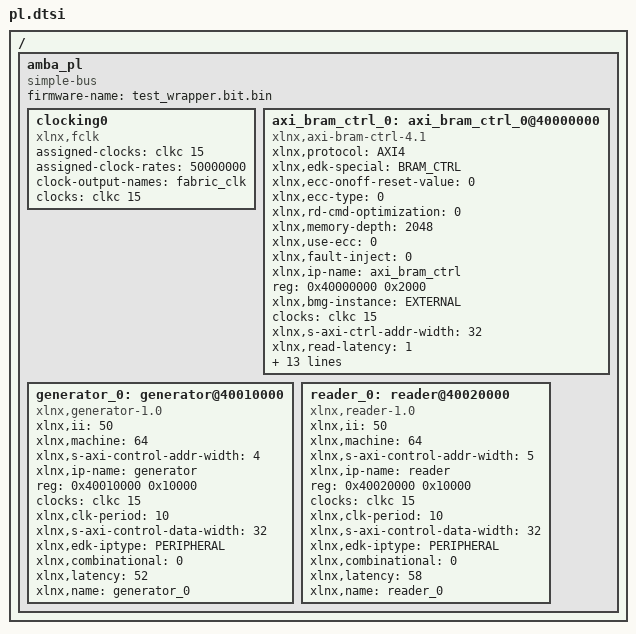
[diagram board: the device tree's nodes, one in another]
/ {
	amba_pl: amba_pl {
		ranges;
		compatible = "simple-bus";
		#address-cells = <1>;
		#size-cells = <1>;
		firmware-name = "test_wrapper.bit.bin";
		clocking0: clocking0 {
			compatible = "xlnx,fclk";
			assigned-clocks = <&clkc 15>;
			assigned-clock-rates = <50000000>;
			#clock-cells = <0>;
			clock-output-names = "fabric_clk";
			clocks = <&clkc 15>;
		};
		axi_bram_ctrl_0: axi_bram_ctrl_0@40000000 {
			xlnx,protocol = "AXI4";
			xlnx,edk-special = "BRAM_CTRL";
			compatible = "xlnx,axi-bram-ctrl-4.1" , "xlnx,axi-bram-ctrl";
			xlnx,ecc-onoff-reset-value = <0>;
			xlnx,ecc-type = <0>;
			xlnx,rd-cmd-optimization = <0>;
			xlnx,memory-depth = <2048>;
			xlnx,use-ecc = <0>;
			xlnx,fault-inject = <0>;
			xlnx,ip-name = "axi_bram_ctrl";
			reg = <0x40000000 0x2000>;
			xlnx,bmg-instance = "EXTERNAL";
			clocks = <&clkc 15>;
			xlnx,s-axi-ctrl-addr-width = <32>;
			xlnx,read-latency = <1>;
			xlnx,id-width = <0>;
			xlnx,s-axi-supports-narrow-burst = <0>;
			xlnx,supports-narrow-burst = <0>;
			xlnx,single-port-bram = <0>;
			xlnx,ecc = <0>;
			xlnx,edk-iptype = "PERIPHERAL";
			status = "okay";
			clock-names = "s_axi_aclk";
			xlnx,data-width = <32>;
			xlnx,bram-addr-width = <11>;
			xlnx,bram-inst-mode = "EXTERNAL";
			xlnx,s-axi-ctrl-data-width = <32>;
			xlnx,mem-depth = <2048>;
			xlnx,s-axi-id-width = <1>;
			xlnx,name = "axi_bram_ctrl_0";
		};
		generator_0: generator@40010000 {
			compatible = "xlnx,generator-1.0";
			xlnx,ii = <50>;
			xlnx,machine = <64>;
			xlnx,s-axi-control-addr-width = <4>;
			xlnx,ip-name = "generator";
			reg = <0x40010000 0x10000>;
			clocks = <&clkc 15>;
			xlnx,clk-period = <10>;
			xlnx,s-axi-control-data-width = <32>;
			xlnx,edk-iptype = "PERIPHERAL";
			status = "okay";
			clock-names = "ap_clk";
			xlnx,combinational = <0>;
			xlnx,latency = <52>;
			xlnx,name = "generator_0";
		};
		reader_0: reader@40020000 {
			compatible = "xlnx,reader-1.0";
			xlnx,ii = <50>;
			xlnx,machine = <64>;
			xlnx,s-axi-control-addr-width = <5>;
			xlnx,ip-name = "reader";
			reg = <0x40020000 0x10000>;
			clocks = <&clkc 15>;
			xlnx,clk-period = <10>;
			xlnx,s-axi-control-data-width = <32>;
			xlnx,edk-iptype = "PERIPHERAL";
			status = "okay";
			clock-names = "ap_clk";
			xlnx,combinational = <0>;
			xlnx,latency = <58>;
			xlnx,name = "reader_0";
		};
	};
};
